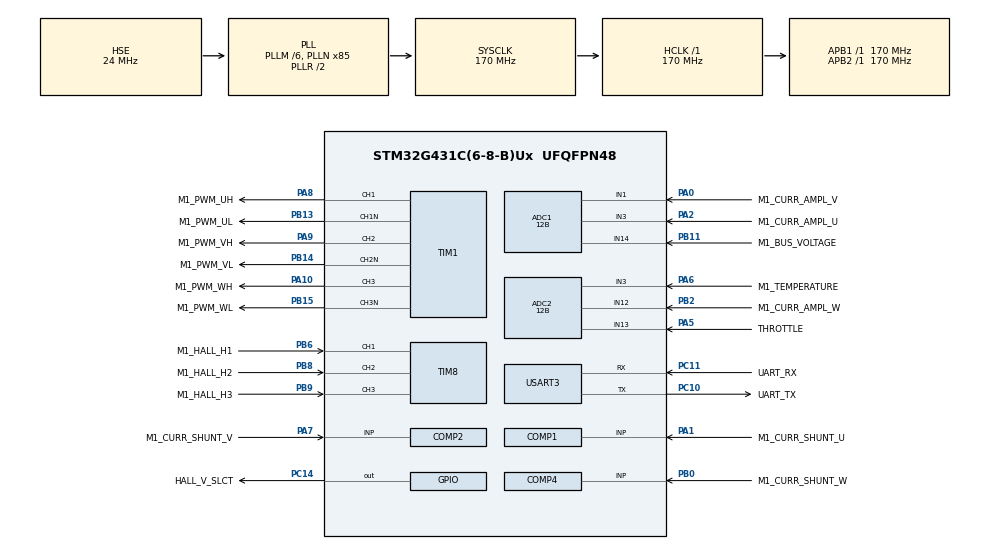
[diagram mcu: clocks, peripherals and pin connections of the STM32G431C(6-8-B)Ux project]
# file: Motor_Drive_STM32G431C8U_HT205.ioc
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ADC1.Channel-1\#ChannelRegularConversion=ADC_CHANNEL_14
ADC1.ClockPrescaler=ADC_CLOCK_ASYNC_DIV4
ADC1.ContinuousConvMode=DISABLE
ADC1.DMAContinuousRequests=DISABLE
ADC1.DataAlign=ADC_DATAALIGN_LEFT
ADC1.DiscontinuousConvMode=DISABLE
ADC1.EOCSelection=ADC_EOC_SINGLE_CONV
ADC1.EnableAnalogWatchDog1=false
ADC1.EnableAnalogWatchDog2=false
ADC1.EnableAnalogWatchDog3=false
ADC1.EnableInjectedConversion=ENABLE
ADC1.EnableRegularConversion=ENABLE
ADC1.ExternalTrigConv=ADC_SOFTWARE_START
ADC1.ExternalTrigConvEdge=ADC_EXTERNALTRIGCONVEDGE_NONE
ADC1.ExternalTrigInjecConv=ADC_EXTERNALTRIGINJEC_T1_TRGO
ADC1.ExternalTrigInjecConvEdge=ADC_EXTERNALTRIGINJECCONV_EDGE_RISING
ADC1.InjNumberOfConversion=2
ADC1.InjectedChannel-1\#ChannelInjectedConversion=ADC_CHANNEL_3
ADC1.InjectedChannel-2\#ChannelInjectedConversion=ADC_CHANNEL_1
ADC1.InjectedConvMode=None
ADC1.InjectedOffset-1\#ChannelInjectedConversion=0
ADC1.InjectedOffset-2\#ChannelInjectedConversion=0
ADC1.InjectedOffsetNumber-1\#ChannelInjectedConversion=ADC_OFFSET_NONE
ADC1.InjectedOffsetNumber-2\#ChannelInjectedConversion=ADC_OFFSET_NONE
ADC1.InjectedRank-1\#ChannelInjectedConversion=1
ADC1.InjectedRank-2\#ChannelInjectedConversion=2
ADC1.InjectedSamplingTime-1\#ChannelInjectedConversion=ADC_SAMPLETIME_6CYCLES_5
ADC1.InjectedSamplingTime-2\#ChannelInjectedConversion=ADC_SAMPLETIME_6CYCLES_5
ADC1.LowPowerAutoWait=DISABLE
ADC1.NbrOfConversion=1
ADC1.NbrOfConversionFlag=1
ADC1.Offset-1\#ChannelRegularConversion=0
ADC1.OffsetNumber-1\#ChannelRegularConversion=ADC_OFFSET_NONE
ADC1.Overrun=ADC_OVR_DATA_PRESERVED
ADC1.Rank-1\#ChannelRegularConversion=1
ADC1.Resolution=ADC_RESOLUTION_12B
ADC1.SamplingTime-1\#ChannelRegularConversion=ADC_SAMPLETIME_24CYCLES_5
ADC1.ScanConvMode=ADC_SCAN_ENABLE
ADC1.master=1
ADC2.Channel-1\#ChannelRegularConversion=ADC_CHANNEL_3
ADC2.Channel-3\#ChannelRegularConversion=ADC_CHANNEL_13
ADC2.ClockPrescaler=ADC_CLOCK_ASYNC_DIV4
ADC2.ContinuousConvMode=DISABLE
ADC2.DMAContinuousRequests=DISABLE
ADC2.DataAlign=ADC_DATAALIGN_LEFT
ADC2.DiscontinuousConvMode=DISABLE
ADC2.EOCSelection=ADC_EOC_SINGLE_CONV
ADC2.EnableAnalogWatchDog1=false
ADC2.EnableAnalogWatchDog2=false
ADC2.EnableAnalogWatchDog3=false
ADC2.EnableInjectedConversion=ENABLE
ADC2.EnableRegularConversion=ENABLE
ADC2.ExternalTrigConv=ADC_SOFTWARE_START
ADC2.ExternalTrigConvEdge=ADC_EXTERNALTRIGCONVEDGE_NONE
ADC2.ExternalTrigInjecConv=ADC_EXTERNALTRIGINJEC_T1_TRGO
ADC2.ExternalTrigInjecConvEdge=ADC_EXTERNALTRIGINJECCONV_EDGE_RISING
ADC2.InjNumberOfConversion=2
ADC2.InjectedChannel-1\#ChannelInjectedConversion=ADC_CHANNEL_1
ADC2.InjectedChannel-2\#ChannelInjectedConversion=ADC_CHANNEL_12
ADC2.InjectedConvMode=None
ADC2.InjectedOffset-1\#ChannelInjectedConversion=0
ADC2.InjectedOffset-2\#ChannelInjectedConversion=0
ADC2.InjectedOffsetNumber-1\#ChannelInjectedConversion=ADC_OFFSET_NONE
ADC2.InjectedOffsetNumber-2\#ChannelInjectedConversion=ADC_OFFSET_NONE
ADC2.InjectedRank-1\#ChannelInjectedConversion=1
ADC2.InjectedRank-2\#ChannelInjectedConversion=2
ADC2.InjectedSamplingTime-1\#ChannelInjectedConversion=ADC_SAMPLETIME_6CYCLES_5
ADC2.InjectedSamplingTime-2\#ChannelInjectedConversion=ADC_SAMPLETIME_6CYCLES_5
ADC2.LowPowerAutoWait=DISABLE
ADC2.NbrOfConversion=2
ADC2.NbrOfConversionFlag=1
ADC2.Offset-1\#ChannelRegularConversion=0
ADC2.OffsetNumber-1\#ChannelRegularConversion=ADC_OFFSET_NONE
ADC2.OffsetNumber-3\#ChannelRegularConversion=ADC_OFFSET_NONE
ADC2.Overrun=ADC_OVR_DATA_PRESERVED
ADC2.Rank-1\#ChannelRegularConversion=1
ADC2.Rank-3\#ChannelRegularConversion=2
ADC2.Resolution=ADC_RESOLUTION_12B
ADC2.SamplingTime-1\#ChannelRegularConversion=ADC_SAMPLETIME_24CYCLES_5
ADC2.SamplingTime-3\#ChannelRegularConversion=ADC_SAMPLETIME_24CYCLES_5
ADC2.ScanConvMode=ADC_SCAN_ENABLE
DAC3.DAC_Channel-DAC_OUT2_Int=DAC_CHANNEL_2
ExtraMW=MotorControl
ExtraMW.MotorControl.Config=MotorControl
ExtraMW.MotorControl.Mode=MotorControl
ExtraMW.MotorControl.Root=MCSDK_v5.4.6/MotorControl
ExtraMW.MotorControl.Template=templates
FREERTOS.Tasks01=mediumFrequency,24,128,startMediumFrequencyTask,As weak,NULL,Dynamic,NULL,NULL;safety,32,128,StartSafetyTask,As external,NULL,Dynamic,NULL,NULL;debugTask,8,128,startDebugTask,Default,NULL,Dynamic,NULL,NULL
Mcu.Family=STM32G4
Mcu.Name=STM32G431C(6-8-B)Ux
Mcu.Package=UFQFPN48
MotorControl.ADC_1_PERIPH=ADC1
MotorControl.ADC_2_PERIPH=ADC2
MotorControl.ADC_AHBPERIPH=RCC_AHBPeriph_ADC12
MotorControl.ADC_CLOCK_WB_DIV=4
MotorControl.ADC_CLOCK_WB_FREQ=42.5
MotorControl.ADC_PERIPH=ADC1
MotorControl.ADC_REFERENCE_VOLTAGE=3.30
MotorControl.ALIGNMENT_ANGLE_DEG=90
MotorControl.ALIGNMENT_DURATION=700
MotorControl.AMPLIFICATION_GAIN=20.00
MotorControl.ANGC={0,0,0,0,0,0,0,0}
MotorControl.BEMF_CONSISTENCY_GAIN=64
MotorControl.BEMF_CONSISTENCY_TOL=64
MotorControl.BKIN1_FILTER=0
MotorControl.BKIN2_FILTER=3
MotorControl.BKIN2_MODE=INT_MODE
MotorControl.BKIN_MODE=NONE
MotorControl.BOARD=CUSTOM
MotorControl.BRKIN2_GPIO_AF=GPIO_AF_12
MotorControl.BRKIN_GPIO_AF=GPIO_AF_2
MotorControl.BUS_VOLTAGE_READING=true
MotorControl.CCMRAM_ENABLED=false
MotorControl.CLOCK_FREQUENCY=CPU_CLK_170_MHZ
MotorControl.CLOCK_SOURCE=EXTERNAL
MotorControl.CONSTANT1_D=160849
MotorControl.CONSTANT1_Q=160849
MotorControl.CONSTANT2_QD=72703
MotorControl.CORD_BEMF_CONSISTENCY_GAIN=64
MotorControl.CORD_BEMF_CONSISTENCY_TOL=64
MotorControl.CORD_F1=16384
MotorControl.CORD_F2=16384
MotorControl.CORD_FIFO_DEPTH_01HZ=64
MotorControl.CORD_FIFO_DEPTH_DPP=64
MotorControl.CORD_GAIN1=-21504
MotorControl.CORD_GAIN2=24227
MotorControl.CORD_MAX_ACCEL_DPPP=887
MotorControl.CORD_MEAS_ERRORS_BEFORE_FAULTS=3
MotorControl.CORD_VARIANCE_THRESHOLD=4
MotorControl.CPU_CLK_170_MHZ=true
MotorControl.CTRBDID=29
MotorControl.CUBE_MX_VER=6.2.0
MotorControl.CURRENT_READING_TOPOLOGY=THREE_SHUNT_INDEPENDENT_RESOURCES
MotorControl.CURR_SAMPLING_TIME=6
MotorControl.DAC_EMULATED=false
MotorControl.DAC_FUNCTIONALITY=false
MotorControl.DAC_OCP_A_M1=DAC3_CH1
MotorControl.DAC_OCP_B_M1=DAC3_CH2
MotorControl.DAC_OCP_C_M1=DAC3_CH2
MotorControl.DAC_OVP_M1=DAC3_CH1
MotorControl.DAC_TIMER_CH1_GPIO_PIN=LL_GPIO_PIN_0
MotorControl.DAC_TIMER_CH1_GPIO_PORT=GPIOA
MotorControl.DAC_TIMER_CH2_GPIO_PIN=LL_GPIO_PIN_0
MotorControl.DAC_TIMER_CH2_GPIO_PORT=GPIOA
MotorControl.DAC_TIMER_SELECTION=TIM3
MotorControl.DC_CURRENT_RS_MEAS=10.00
MotorControl.DEBUG_DAC_CH1=false
MotorControl.DEBUG_DAC_CH2=false
MotorControl.DEFAULT_CONTROL_MODE=STC_TORQUE_MODE
MotorControl.DEFAULT_DAC_CHANNEL_1=MC_PROTOCOL_REG_I_A
MotorControl.DEFAULT_DAC_CHANNEL_2=MC_PROTOCOL_REG_I_B
MotorControl.DEFAULT_DAC_MOTOR=0
MotorControl.DEFAULT_FLUX_COMPONENT=0
MotorControl.DEFAULT_TARGET_SPEED_RPM=1500
MotorControl.DEFAULT_TORQUE_COMPONENT=0
MotorControl.DISSIPATIVE_BRAKE_POLARITY=DOUT_ACTIVE_HIGH
MotorControl.DRIVES_NUMBER_SELECTION=SINGLEDRIVE
MotorControl.EMERGENCY2_STOP_GPIO_PIN=LL_GPIO_PIN_11
MotorControl.EMERGENCY2_STOP_GPIO_PORT=GPIOA
MotorControl.EMERGENCY_STOP_GPIO_PIN=LL_GPIO_PIN_11
MotorControl.EMERGENCY_STOP_GPIO_PORT=GPIOA
MotorControl.ENABLE_SL_ALGO_FROM_PHASE=3
MotorControl.ENCODER_AVAILABLE=false
MotorControl.ENCODER_PPR=400
MotorControl.ENC_AVERAGING_FIFO_DEPTH=16
MotorControl.ENC_A_GPIO_PIN=LL_GPIO_PIN_0
MotorControl.ENC_A_GPIO_PORT=GPIOA
MotorControl.ENC_B_GPIO_PIN=LL_GPIO_PIN_3
MotorControl.ENC_B_GPIO_PORT=GPIOB
MotorControl.ENC_ICx_FILTER=119
MotorControl.ENC_INVERT_SPEED=false
MotorControl.ENC_MEAS_ERRORS_BEFORE_FAULTS=3
MotorControl.ENC_TIMER_REMAPPING=NO_REMAP_TIM2
MotorControl.ENC_TIMER_SELECTION=ENC_TIM2
MotorControl.ENC_USE_CH3=false
MotorControl.EXT_CLK_8_MHZ=true
MotorControl.EXT_CLOCK_FREQUENCY=EXT_CLK_8_MHZ
MotorControl.F1=16384
MotorControl.F2=16384
MotorControl.FEEDBACK_NET_FILTERING=false
MotorControl.FEED_FORWARD_CURRENT_REG_ENABLING=false
MotorControl.FINAL_I_ALIGNMENT=1548
MotorControl.FLUX_WEAKENING_ENABLING=false
MotorControl.FW_KIDIV=32768
MotorControl.FW_KI_GAIN=5000
MotorControl.FW_KPDIV=32768
MotorControl.FW_KP_GAIN=3000
MotorControl.FW_VOLTAGE_REF=985
MotorControl.GAIN1=-21504
MotorControl.GAIN2=24227
MotorControl.H1_GPIO_PIN=LL_GPIO_PIN_6
MotorControl.H1_GPIO_PORT=GPIOB
MotorControl.H2_GPIO_PIN=LL_GPIO_PIN_7
MotorControl.H2_GPIO_PORT=GPIOB
MotorControl.H3_GPIO_PIN=LL_GPIO_PIN_8
MotorControl.H3_GPIO_PORT=GPIOB
MotorControl.HALL_AVERAGING_FIFO_DEPTH=6
MotorControl.HALL_ICx_FILTER=190
MotorControl.HALL_MEAS_ERRORS_BEFORE_FAULTS=3
MotorControl.HALL_MTPA=false
MotorControl.HALL_PHASE_SHIFT=60
MotorControl.HALL_SENSORS=true
MotorControl.HALL_SENSORS_AVAILABLE=true
MotorControl.HALL_SENSORS_PLACEMENT=DEGREES_120
MotorControl.HALL_TIMER_REMAPPING=NO_REMAP_TIM4
MotorControl.HALL_TIMER_SELECTION=HALL_TIM4
MotorControl.HFI_AMPLITUDE=25
MotorControl.HFI_DC_0_COEFF=0.00146
MotorControl.HFI_DC_1_COEFF=0.002921
MotorControl.HFI_DC_2_COEFF=0.00146
MotorControl.HFI_DC_3_COEFF=1.889033
MotorControl.HFI_DC_4_COEFF=-0.894874
MotorControl.HFI_DEBUG_MODE=false
MotorControl.HFI_FREQUENCY=400
MotorControl.HFI_HIFRAMPLSCAN=25
MotorControl.HFI_HP_ID_0_COEFF=0.883002
MotorControl.HFI_HP_ID_1_COEFF=-1.766004
MotorControl.HFI_HP_ID_2_COEFF=0.883002
MotorControl.HFI_HP_ID_3_COEFF=1.752268
MotorControl.HFI_HP_ID_4_COEFF=-0.779739
MotorControl.HFI_IDH_DELAY=32400
MotorControl.HFI_LOCKFREQ=66
MotorControl.HFI_LP_ID_0_COEFF=0.021558
MotorControl.HFI_LP_ID_1_COEFF=0.043117
MotorControl.HFI_LP_ID_2_COEFF=0.021558
MotorControl.HFI_LP_ID_3_COEFF=1.543836
MotorControl.HFI_LP_ID_4_COEFF=-0.63007
MotorControl.HFI_MAXANGLEDIFF=3640
MotorControl.HFI_MINIMUM_SPEED_RPM=402
MotorControl.HFI_NOTCH_IQD_0_COEFF=0.941467
MotorControl.HFI_NOTCH_IQD_1_COEFF=-1.823778
MotorControl.HFI_NOTCH_IQD_2_COEFF=0.941467
MotorControl.HFI_NOTCH_IQD_3_COEFF=1.823778
MotorControl.HFI_NOTCH_IQD_4_COEFF=-0.882933
MotorControl.HFI_NSDETPOINTSSKIP=10
MotorControl.HFI_NSMAXDETPOINTS=20
MotorControl.HFI_NS_MIN_SAT_DIFF=0
MotorControl.HFI_PID_KIDIV=32768
MotorControl.HFI_PID_KI_DEFAULT=400
MotorControl.HFI_PID_KPDIV=16384
MotorControl.HFI_PID_KP_DEFAULT=800
MotorControl.HFI_PLL_KI_DEFAULT=0.00400
MotorControl.HFI_PLL_KP_DEFAULT=0.00060
MotorControl.HFI_RESTARTTIMESEC=0.1
MotorControl.HFI_RESTART_RPM_TH=(((HFI_STO_RPM_TH)+(STO_HFI_RPM_TH))/2)
MotorControl.HFI_REVERT_DIRECTION=true
MotorControl.HFI_SCANROTATIONSNO=3
MotorControl.HFI_SPD_BUFFER_DEPTH_01HZ=64
MotorControl.HFI_STEPANGLE=3640
MotorControl.HFI_STO_RPM_TH=OBS_MINIMUM_SPEED_RPM
MotorControl.HFI_WAITAFTERNS2=4
MotorControl.HFI_WAITBEFORESN=6
MotorControl.HFI_WAITSYNCH=20
MotorControl.HFI_WAITTRACK=20
MotorControl.HIGH_SIDE_BRAKE_STATE=false
MotorControl.HIGH_SIDE_IDLE_STATE=false
MotorControl.HW_COMPLEMENTED_LOW_SIDE=false
MotorControl.HW_DEAD_TIME_NS=100
MotorControl.HW_OV_CURRENT_PROT_BYPASS=false
MotorControl.ID_DEMAG=-7943
MotorControl.INRUSH_CURRLIMIT_AT_POWER_ON=true
MotorControl.INRUSH_CURRLIMIT_CHANGE_AFTER_MS=1000
MotorControl.INRUSH_CURRLIMIT_ENABLING=false
MotorControl.INRUSH_CURRLIMIT_GPIO_PIN=LL_GPIO_PIN_4
MotorControl.INRUSH_CURRLIMIT_GPIO_PORT=GPIOE
MotorControl.INRUSH_CURR_LIMITER_POLARITY=DOUT_ACTIVE_HIGH
MotorControl.INTERNAL_OVERCURRENTPROTECTION=true
MotorControl.INTERNAL_OVERVOLTAGEPROTECTION=false
MotorControl.IPs=CORDIC,NVIC,RCC,MotorControl,TIM1,COMP1,DAC3,COMP2,COMP4,ADC1,ADC2,TIM4,USART2,FREERTOS
MotorControl.IQMAX=7943
MotorControl.LCD_JOYSTICK_FUNCTIONALITY=false
MotorControl.LCD_MODE=LCD_FULL
MotorControl.LDLQ_RATIO=1.000
MotorControl.LOW_SIDE_BRAKE_STATE=false
MotorControl.LOW_SIDE_IDLE_STATE=false
MotorControl.LOW_SIDE_SIGNALS_ENABLING=LS_PWM_TIMER
MotorControl.LS=0.000200
MotorControl.MAX_APPLICATION_SPEED=400
MotorControl.MAX_MODULATION_93_PER_CENT=true
MotorControl.MAX_MODULATION_INDEX=MAX_MODULATION_93_PER_CENT
MotorControl.MCU=STM32G431CB
MotorControl.MCU_TYPE=STM32G431CB
MotorControl.MC_WORKBENCH_VERSION=5.4.6.21068
MotorControl.MEAS_ERRORS_BEFORE_FAULTS=3
MotorControl.MIN_APPLICATION_SPEED=0
MotorControl.MOTOR_MAX_SPEED_RPM=400
MotorControl.MOTOR_TYPE=PMSM
MotorControl.MOTOR_VOLTAGE_CONSTANT=88.0
MotorControl.MTPA_ENABLING=false
MotorControl.NB_CONSECUTIVE_TESTS=2
MotorControl.NOMINAL_BUS_VOLTAGE_V=42
MotorControl.NOMINAL_CURRENT=7943
MotorControl.OBS_MEAS_ERRORS_BEFORE_FAULTS=3
MotorControl.OBS_MINIMUM_SPEED_RPM=580
MotorControl.OCPA_DAC_INTERNAL_PIN=true
MotorControl.OCPA_INVERTINGINPUT=COMPX_InvertingInput_DAC3
MotorControl.OCPA_INVERTINGINPUT_DAC_OUT=OUT1
MotorControl.OCPA_INVERTINGINPUT_GPIO_PIN=LL_GPIO_PIN_4
MotorControl.OCPA_INVERTINGINPUT_GPIO_PORT=GPIOA
MotorControl.OCPA_INVERTINGINPUT_MODE=INT_MODE
MotorControl.OCPA_NONINVERTINGINPUT=COMP1_NonInvertingInput_PA1
MotorControl.OCPA_NONINVERTINGINPUT_GPIO_PIN=LL_GPIO_PIN_1
MotorControl.OCPA_NONINVERTINGINPUT_GPIO_PORT=GPIOA
MotorControl.OCPA_OUTPUT=COMP_Output_TIM1BKIN2
MotorControl.OCPA_OUTPUTPOL=COMP_OutputPol_NonInverted
MotorControl.OCPA_OUTPUT_GPIO_AF=GPIO_AF_2
MotorControl.OCPA_OUTPUT_GPIO_PIN=LL_GPIO_PIN_0
MotorControl.OCPA_OUTPUT_GPIO_PORT=GPIOA
MotorControl.OCPA_OUTPUT_MODE=INT_MODE
MotorControl.OCPA_SELECTION=COMP1
MotorControl.OCPB_DAC_INTERNAL_PIN=true
MotorControl.OCPB_INVERTINGINPUT=COMPX_InvertingInput_DAC3
MotorControl.OCPB_INVERTINGINPUT_DAC_OUT=OUT2
MotorControl.OCPB_INVERTINGINPUT_GPIO_PIN=LL_GPIO_PIN_4
MotorControl.OCPB_INVERTINGINPUT_GPIO_PORT=GPIOA
MotorControl.OCPB_INVERTINGINPUT_MODE=INT_MODE
MotorControl.OCPB_NONINVERTINGINPUT=COMP2_NonInvertingInput_PA7
MotorControl.OCPB_NONINVERTINGINPUT_GPIO_PIN=LL_GPIO_PIN_7
MotorControl.OCPB_NONINVERTINGINPUT_GPIO_PORT=GPIOA
MotorControl.OCPB_OUTPUT=COMP_Output_TIM1BKIN2
MotorControl.OCPB_OUTPUTPOL=COMP_OutputPol_NonInverted
MotorControl.OCPB_OUTPUT_GPIO_AF=GPIO_AF_2
MotorControl.OCPB_OUTPUT_GPIO_PIN=LL_GPIO_PIN_2
MotorControl.OCPB_OUTPUT_GPIO_PORT=GPIOA
MotorControl.OCPB_OUTPUT_MODE=INT_MODE
MotorControl.OCPB_SELECTION=COMP2
MotorControl.OCPC_DAC_INTERNAL_PIN=true
MotorControl.OCPC_INVERTINGINPUT=COMPX_InvertingInput_DAC3
MotorControl.OCPC_INVERTINGINPUT_DAC_OUT=OUT2
MotorControl.OCPC_INVERTINGINPUT_GPIO_PIN=LL_GPIO_PIN_4
MotorControl.OCPC_INVERTINGINPUT_GPIO_PORT=GPIOA
MotorControl.OCPC_INVERTINGINPUT_MODE=INT_MODE
MotorControl.OCPC_NONINVERTINGINPUT=COMP4_NonInvertingInput_PB0
MotorControl.OCPC_NONINVERTINGINPUT_GPIO_PIN=LL_GPIO_PIN_0
MotorControl.OCPC_NONINVERTINGINPUT_GPIO_PORT=GPIOB
MotorControl.OCPC_OUTPUT=COMP_Output_TIM1BKIN2
MotorControl.OCPC_OUTPUTPOL=COMP_OutputPol_NonInverted
MotorControl.OCPC_OUTPUT_GPIO_AF=GPIO_AF_2
MotorControl.OCPC_OUTPUT_GPIO_PIN=LL_GPIO_PIN_1
MotorControl.OCPC_OUTPUT_GPIO_PORT=GPIOB
MotorControl.OCPC_OUTPUT_MODE=INT_MODE
MotorControl.OCPC_SELECTION=COMP4
MotorControl.OCPREF=9532
MotorControl.OCP_COMP_THRESHOLD=0.50
MotorControl.OCP_FILTER=COMP_Mode_HighSpeed
MotorControl.OCP_INVERTINGINPUT=COMPX_InvertingInput_DAC3
MotorControl.OCP_INVERTINGINPUT_GPIO_PIN=LL_GPIO_PIN_4
MotorControl.OCP_INVERTINGINPUT_GPIO_PORT=GPIOA
MotorControl.OCP_INVERTINGINPUT_MODE=INT_MODE
MotorControl.OCP_NONINVERTINGINPUT=COMP2_NonInvertingInput_PA7
MotorControl.OCP_NONINVERTINGINPUT_GPIO_PIN=LL_GPIO_PIN_7
MotorControl.OCP_NONINVERTINGINPUT_GPIO_PORT=GPIOA
MotorControl.OCP_OUTPUT=COMP_Output_TIM1BKIN2
MotorControl.OCP_OUTPUTPOL=COMP_OutputPol_NonInverted
MotorControl.OCP_OUTPUT_GPIO_AF=GPIO_AF_2
MotorControl.OCP_OUTPUT_GPIO_PIN=LL_GPIO_PIN_2
MotorControl.OCP_OUTPUT_GPIO_PORT=GPIOA
MotorControl.OCP_OUTPUT_MODE=INT_MODE
MotorControl.OCP_SELECTION=COMP2
MotorControl.OFST={0,0,0,0,0,0,0,0}
MotorControl.ON_OVER_VOLTAGE=TURN_OFF_PWM
MotorControl.OPAMP1_INVERTINGINPUT=OPAMP1_InvertingInput_PGA
MotorControl.OPAMP1_INVERTINGINPUT_GPIO_PIN=LL_GPIO_PIN_3
MotorControl.OPAMP1_INVERTINGINPUT_GPIO_PORT=GPIOA
MotorControl.OPAMP1_INVERTINGINPUT_MODE=INT_MODE
MotorControl.OPAMP1_NONINVERTINGINPUT_PHA=OPAMP1_NonInvertingInput_PA1
MotorControl.OPAMP1_NONINVERTINGINPUT_PHA_GPIO_PIN=LL_GPIO_PIN_1
MotorControl.OPAMP1_NONINVERTINGINPUT_PHA_GPIO_PORT=GPIOA
MotorControl.OPAMP1_NONINVERTINGINPUT_PHB=OPAMP1_NonInvertingInput_PA7
MotorControl.OPAMP1_NONINVERTINGINPUT_PHB_GPIO_PIN=LL_GPIO_PIN_7
MotorControl.OPAMP1_NONINVERTINGINPUT_PHB_GPIO_PORT=GPIOA
MotorControl.OPAMP1_OUT_GPIO_PIN=LL_GPIO_PIN_2
MotorControl.OPAMP1_OUT_GPIO_PORT=GPIOA
MotorControl.OPAMP1_SELECTION=OPAMP1
MotorControl.OPAMP2_INVERTINGINPUT=OPAMP2_InvertingInput_PGA
MotorControl.OPAMP2_INVERTINGINPUT_GPIO_PIN=LL_GPIO_PIN_5
MotorControl.OPAMP2_INVERTINGINPUT_GPIO_PORT=GPIOA
MotorControl.OPAMP2_INVERTINGINPUT_MODE=INT_MODE
MotorControl.OPAMP2_NONINVERTINGINPUT_PHA=OPAMP2_NonInvertingInput_PB0
MotorControl.OPAMP2_NONINVERTINGINPUT_PHA_GPIO_PIN=LL_GPIO_PIN_0
MotorControl.OPAMP2_NONINVERTINGINPUT_PHA_GPIO_PORT=GPIOB
MotorControl.OPAMP2_NONINVERTINGINPUT_PHB=OPAMP2_NonInvertingInput_PA7
MotorControl.OPAMP2_NONINVERTINGINPUT_PHB_GPIO_PIN=LL_GPIO_PIN_7
MotorControl.OPAMP2_NONINVERTINGINPUT_PHB_GPIO_PORT=GPIOA
MotorControl.OPAMP2_NONINVERTINGINPUT_PHC=OPAMP2_NonInvertingInput_PB0
MotorControl.OPAMP2_NONINVERTINGINPUT_PHC_GPIO_PIN=LL_GPIO_PIN_0
MotorControl.OPAMP2_NONINVERTINGINPUT_PHC_GPIO_PORT=GPIOB
MotorControl.OPAMP2_OUT_GPIO_PIN=LL_GPIO_PIN_6
MotorControl.OPAMP2_OUT_GPIO_PORT=GPIOA
MotorControl.OPAMP2_SELECTION=OPAMP2
MotorControl.OPAMP3_INVERTINGINPUT=OPAMP1_InvertingInput_PGA
MotorControl.OPAMP3_INVERTINGINPUT_GPIO_PIN=LL_GPIO_PIN_0
MotorControl.OPAMP3_INVERTINGINPUT_GPIO_PORT=GPIOA
MotorControl.OPAMP3_INVERTINGINPUT_MODE=INT_MODE
MotorControl.OPAMP3_SELECTION=OPAMP1
MotorControl.OPAMP_INVERTINGINPUT=OPAMP1_InvertingInput_PGA
MotorControl.OPAMP_INVERTINGINPUT_GPIO_PIN=LL_GPIO_PIN_3
MotorControl.OPAMP_INVERTINGINPUT_GPIO_PORT=GPIOA
MotorControl.OPAMP_INVERTINGINPUT_MODE=INT_MODE
MotorControl.OPAMP_NONINVERTINGINPUT=OPAMP1_NonInvertingInput_PA7
MotorControl.OPAMP_NONINVERTINGINPUT_GPIO_PIN=LL_GPIO_PIN_7
MotorControl.OPAMP_NONINVERTINGINPUT_GPIO_PORT=GPIOA
MotorControl.OPAMP_OUT_GPIO_PIN=LL_GPIO_PIN_2
MotorControl.OPAMP_OUT_GPIO_PORT=GPIOA
MotorControl.OPAMP_PGACONNECT=OPAMP_PGAConnect_No
MotorControl.OPAMP_PGAGAIN=OPAMP_OPAMP_PGAGain_2
MotorControl.OPAMP_SELECTION=OPAMP1
MotorControl.OPAMP_TYPE_GAIN=INTERNAL
MotorControl.OPEN_LOOP_FOC=false
MotorControl.OPEN_LOOP_K=44
MotorControl.OPEN_LOOP_OFF=4400
MotorControl.OPEN_LOOP_SPEED_RAMP_DURATION_MS=1000
MotorControl.OPEN_LOOP_SPEED_RPM=100
MotorControl.OPEN_LOOP_VF=false
MotorControl.OPEN_LOOP_VOLTAGE_d=6000
MotorControl.OVERCURR_FEEDBACK_POLARITY=EMSTOP_ACTIVE_LOW
MotorControl.OVERCURR_PROTECTION_HW_DISABLING=DOUT_ACTIVE_HIGH
MotorControl.OVPREF=23830
MotorControl.OVP_FILTER=COMP_Mode_HighSpeed
MotorControl.OVP_INVERTINGINPUT=COMPX_InvertingInput_VREF
MotorControl.OVP_INVERTINGINPUT_GPIO_PIN=LL_GPIO_PIN_4
MotorControl.OVP_INVERTINGINPUT_GPIO_PORT=GPIOA
MotorControl.OVP_INVERTINGINPUT_MODE=INT_MODE
MotorControl.OVP_NONINVERTINGINPUT=COMP2_NonInvertingInput_PA7
MotorControl.OVP_NONINVERTINGINPUT_GPIO_PIN=LL_GPIO_PIN_7
MotorControl.OVP_NONINVERTINGINPUT_GPIO_PORT=GPIOA
MotorControl.OVP_OUTPUT=COMP_Output_TIM1BKIN
MotorControl.OVP_OUTPUTPOL=COMP_OutputPol_NonInverted
MotorControl.OVP_OUTPUT_GPIO_AF=GPIO_AF_2
MotorControl.OVP_OUTPUT_GPIO_PIN=LL_GPIO_PIN_2
MotorControl.OVP_OUTPUT_GPIO_PORT=GPIOA
MotorControl.OVP_OUTPUT_MODE=INT_MODE
MotorControl.OVP_SELECTION=COMP2
MotorControl.OV_CURR_BYPASS_GPIO_PIN=LL_GPIO_PIN_11
MotorControl.OV_CURR_BYPASS_GPIO_PORT=GPIOC
MotorControl.OV_TEMPERATURE_HYSTERESIS_C=10
MotorControl.OV_TEMPERATURE_PROT_ENABLING=true
MotorControl.OV_TEMPERATURE_THRESHOLD_C=70
MotorControl.OV_VOLTAGE_PROT_ENABLING=true
MotorControl.OV_VOLTAGE_THRESHOLD_V=49
MotorControl.PHASE1_DURATION=0
MotorControl.PHASE1_FINAL_CURRENT=0
MotorControl.PHASE1_FINAL_SPEED_RPM=0
MotorControl.PHASE2_DURATION=700
MotorControl.PHASE2_FINAL_CURRENT=476
MotorControl.PHASE2_FINAL_SPEED_RPM=0
MotorControl.PHASE3_DURATION=350
MotorControl.PHASE3_FINAL_CURRENT=556
MotorControl.PHASE3_FINAL_SPEED_RPM=630
MotorControl.PHASE4_DURATION=1150
MotorControl.PHASE4_FINAL_CURRENT=556
MotorControl.PHASE4_FINAL_SPEED_RPM=2700
MotorControl.PHASE5_DURATION=0
MotorControl.PHASE5_FINAL_CURRENT=556
MotorControl.PHASE5_FINAL_SPEED_RPM=2700
MotorControl.PHASE_CURRENTS_ADC=ADC1_2
MotorControl.PHASE_CURRENTS_CHANNEL=ADC_CHANNEL_9
MotorControl.PHASE_CURRENTS_GPIO_PIN=LL_GPIO_PIN_0
MotorControl.PHASE_CURRENTS_GPIO_PORT=GPIOA
MotorControl.PHASE_UH_GPIO_AF=GPIO_AF_6
MotorControl.PHASE_UH_GPIO_PIN=LL_GPIO_PIN_8
MotorControl.PHASE_UH_GPIO_PORT=GPIOA
MotorControl.PHASE_UH_POLARITY=H_ACTIVE_HIGH
MotorControl.PHASE_UL_GPIO_AF=GPIO_AF_6
MotorControl.PHASE_UL_GPIO_PIN=LL_GPIO_PIN_13
MotorControl.PHASE_UL_GPIO_PORT=GPIOB
MotorControl.PHASE_UL_POLARITY=L_ACTIVE_HIGH
MotorControl.PHASE_U_CURR_ADC=ADC1
MotorControl.PHASE_U_CURR_CHANNEL=ADC_CHANNEL_3
MotorControl.PHASE_U_GPIO_PIN=LL_GPIO_PIN_2
MotorControl.PHASE_U_GPIO_PORT=GPIOA
MotorControl.PHASE_VH_GPIO_AF=GPIO_AF_6
MotorControl.PHASE_VH_GPIO_PIN=LL_GPIO_PIN_9
MotorControl.PHASE_VH_GPIO_PORT=GPIOA
MotorControl.PHASE_VH_POLARITY=H_ACTIVE_HIGH
MotorControl.PHASE_VL_GPIO_AF=GPIO_AF_6
MotorControl.PHASE_VL_GPIO_PIN=LL_GPIO_PIN_14
MotorControl.PHASE_VL_GPIO_PORT=GPIOB
MotorControl.PHASE_VL_POLARITY=L_ACTIVE_HIGH
MotorControl.PHASE_V_CURR_ADC=ADC1_2
MotorControl.PHASE_V_CURR_CHANNEL=ADC_CHANNEL_1
MotorControl.PHASE_V_GPIO_PIN=LL_GPIO_PIN_0
MotorControl.PHASE_V_GPIO_PORT=GPIOA
MotorControl.PHASE_WH_GPIO_AF=GPIO_AF_6
MotorControl.PHASE_WH_GPIO_PIN=LL_GPIO_PIN_10
MotorControl.PHASE_WH_GPIO_PORT=GPIOA
MotorControl.PHASE_WH_POLARITY=H_ACTIVE_HIGH
MotorControl.PHASE_WL_GPIO_AF=GPIO_AF_4
MotorControl.PHASE_WL_GPIO_PIN=LL_GPIO_PIN_15
MotorControl.PHASE_WL_GPIO_PORT=GPIOB
MotorControl.PHASE_WL_POLARITY=L_ACTIVE_HIGH
MotorControl.PHASE_W_CURR_ADC=ADC2
MotorControl.PHASE_W_CURR_CHANNEL=ADC_CHANNEL_12
MotorControl.PHASE_W_GPIO_PIN=LL_GPIO_PIN_2
MotorControl.PHASE_W_GPIO_PORT=GPIOB
MotorControl.PID_FLUX_KD_DEFAULT=100
MotorControl.PID_FLUX_KI_DEFAULT=3218
MotorControl.PID_FLUX_KP_DEFAULT=3218
MotorControl.PID_SPEED_KD_DEFAULT=0
MotorControl.PID_SPEED_KI_DEFAULT=700
MotorControl.PID_SPEED_KP_DEFAULT=1000
MotorControl.PID_TORQUE_KD_DEFAULT=100
MotorControl.PID_TORQUE_KI_DEFAULT=3218
MotorControl.PID_TORQUE_KP_DEFAULT=3218
MotorControl.PLL_KI_GAIN=34
MotorControl.PLL_KP_GAIN=489
MotorControl.POLE_PAIR_NUM=23
MotorControl.POSITION_CTRL_ENABLING=false
MotorControl.PWBDID=0
MotorControl.PWM_FREQUENCY=20000
MotorControl.PWM_TIMER_REMAPPING=PWM_PARTIAL_REMAP
MotorControl.PWM_TIMER_SELECTION=PWM_TIM1
MotorControl.REGCONVADC=ADC1
MotorControl.REGULATION_EXECUTION_RATE=2
MotorControl.RS=0.50
MotorControl.RSHUNT=0.00200
MotorControl.RTOS=FREERTOS
MotorControl.RTOS_TIMER=TIM6
MotorControl.RTOS_USE_IRQ=false
MotorControl.R_BRAKE_GPIO_PIN=LL_GPIO_PIN_5
MotorControl.R_BRAKE_GPIO_PORT=GPIOE
MotorControl.R_BRAKE_SWITCH_OFF_THRES_V=39
MotorControl.SEGDIV=0
MotorControl.SERIAL_COMMUNICATION=true
MotorControl.SERIAL_COM_CHANNEL1=MC_PROTOCOL_REG_I_A
MotorControl.SERIAL_COM_CHANNEL2=MC_PROTOCOL_REG_I_A
MotorControl.SERIAL_COM_MODE=COM_BIDIRECTIONAL
MotorControl.SERIAL_COM_MOTOR=0
MotorControl.SHARED_SIGNAL_ENABLE=false
MotorControl.SINGLEDRIVE=true
MotorControl.SPD_DIFFERENTIAL_TERM_ENABLING=false
MotorControl.SPEED_BAND_LOWER_LIMIT=15
MotorControl.SPEED_BAND_UPPER_LIMIT=17
MotorControl.SPEED_LOOP_FREQUENCY_HZ=1000
MotorControl.SPEED_SENSOR_SELECTION=HALL_SENSORS
MotorControl.SP_KDDIV=16
MotorControl.SP_KIDIV=256
MotorControl.SP_KPDIV=16
MotorControl.STARTING_ANGLE_DEG=90
MotorControl.START_STOP_BTN=false
MotorControl.START_STOP_GPIO_PIN=LL_GPIO_PIN_13
MotorControl.START_STOP_GPIO_PORT=GPIOC
MotorControl.START_STOP_POLARITY=DIN_ACTIVE_LOW
MotorControl.START_STOP_POLARITY_EDGE=GPIO_NOPULL
MotorControl.STM32G431CB=true
MotorControl.STO_FIFO_DEPTH_01HZ=64
MotorControl.STO_FIFO_DEPTH_DPP=64
MotorControl.STO_HFI_RPM_TH=460
MotorControl.SW_DEADTIME_NS=500
MotorControl.SW_OV_CURRENT_PROT_ENABLING=true
MotorControl.T0_C=25
MotorControl.TEMPERATURE_READING=true
MotorControl.TEMP_ADC_SAMPLING_TIME=24
MotorControl.TEMP_FDBK_ADC=ADC2
MotorControl.TEMP_FDBK_CHANNEL=ADC_CHANNEL_3
MotorControl.TEMP_FDBK_GPIO_PIN=LL_GPIO_PIN_6
MotorControl.TEMP_FDBK_GPIO_PORT=GPIOA
MotorControl.TFDIFFERENTIAL_TERM_ENABLING=false
MotorControl.TF_KDDIV=8192
MotorControl.TF_KIDIV=16384
MotorControl.TF_KPDIV=4096
MotorControl.THREE_SHUNT_INDEPENDENT_RESOURCES=true
MotorControl.TNOISE_NS=2550
MotorControl.TRANSITION_DURATION=25
MotorControl.TRISE_NS=2550
MotorControl.T_MAX=70
MotorControl.UD_VOLTAGE_THRESHOLD_V=12
MotorControl.USART_REMAPPING=NO_REMAP_USART2
MotorControl.USART_RX_GPIO_PIN=LL_GPIO_PIN_4
MotorControl.USART_RX_GPIO_PORT=GPIOB
MotorControl.USART_SELECTION=USE_USART2
MotorControl.USART_SPEED=115200
MotorControl.USART_TX_GPIO_PIN=LL_GPIO_PIN_3
MotorControl.USART_TX_GPIO_PORT=GPIOB
MotorControl.USE_3OPAMPS=false
MotorControl.USE_INTERNAL_OPAMP=false
MotorControl.UV_VOLTAGE_PROT_ENABLING=false
MotorControl.V0_V=0.290
MotorControl.VARIANCE_THRESHOLD=0.1
MotorControl.VBUS_ADC=ADC1
MotorControl.VBUS_ADC_SAMPLING_TIME=24
MotorControl.VBUS_CHANNEL=ADC_CHANNEL_14
MotorControl.VBUS_GPIO_PIN=LL_GPIO_PIN_11
MotorControl.VBUS_GPIO_PORT=GPIOB
MotorControl.VBUS_PARTITIONING_FACTOR=0.0625
MotorControl.WB_to_Mx_template_version=21-02-18
MotorControl.WB_to_Mx_version=1.2.3
MotorControl.dV_dT=0.025
NVIC.ADC1_2_IRQn=true\:2\:0\:true\:true\:false\:3\:false\:true\:true
NVIC.PriorityGroup=NVIC_PRIORITYGROUP_4
NVIC.TIM1_BRK_TIM15_IRQn=true\:4\:0\:true\:true\:false\:1\:false\:true\:true
NVIC.TIM1_UP_TIM16_IRQn=true\:0\:0\:true\:true\:false\:2\:false\:true\:true
NVIC.TIM2_IRQn=true\:5\:0\:false\:false\:true\:true\:true\:true
NVIC.TIM3_IRQn=true\:5\:0\:false\:false\:true\:true\:true\:true
NVIC.TIM4_IRQn=true\:5\:0\:false\:false\:true\:true\:true\:true
NVIC.TIM6_DAC_IRQn=true\:0\:0\:false\:false\:true\:false\:false\:true
NVIC.TIM8_CC_IRQn=true\:5\:0\:false\:false\:true\:true\:true\:true
NVIC.TIM8_UP_IRQn=true\:5\:0\:false\:false\:true\:true\:true\:true
NVIC.TimeBase=TIM6_DAC_IRQn
NVIC.TimeBaseIP=TIM6
NVIC.USART3_IRQn=true\:5\:0\:false\:false\:true\:true\:true\:true
PA0.GPIO_Label=M1_CURR_AMPL_V
PA0.Signal=SharedAnalog_PA0
PA1.GPIO_Label=M1_CURR_SHUNT_U
PA1.Mode=INP
PA1.Signal=COMP1_INP
PA10.GPIO_Label=M1_PWM_WH
PA10.GPIO_PuPd=GPIO_PULLDOWN
PA10.GPIO_Speed=GPIO_SPEED_FREQ_HIGH
PA10.Signal=S_TIM1_CH3
PA13.GPIO_Label=TMS
PA13.Mode=Serial_Wire
PA13.Signal=SYS_JTMS-SWDIO
PA14.GPIO_Label=TCK
PA14.Mode=Serial_Wire
PA14.Signal=SYS_JTCK-SWCLK
PA2.GPIO_Label=M1_CURR_AMPL_U
PA2.Mode=IN3-Single-Ended
PA2.Signal=ADC1_IN3
PA5.GPIO_Label=THROTTLE
PA5.Mode=IN13-Single-Ended
PA5.Signal=ADC2_IN13
PA6.GPIO_Label=M1_TEMPERATURE
PA6.Mode=IN3-Single-Ended
PA6.Signal=ADC2_IN3
PA7.GPIO_Label=M1_CURR_SHUNT_V
PA7.Mode=INP
PA7.Signal=COMP2_INP
PA8.GPIO_Label=M1_PWM_UH
PA8.GPIO_PuPd=GPIO_PULLDOWN
PA8.GPIO_Speed=GPIO_SPEED_FREQ_HIGH
PA8.Signal=S_TIM1_CH1
PA9.GPIO_Label=M1_PWM_VH
PA9.GPIO_PuPd=GPIO_PULLDOWN
PA9.GPIO_Speed=GPIO_SPEED_FREQ_HIGH
PA9.Signal=S_TIM1_CH2
PB0.GPIO_Label=M1_CURR_SHUNT_W
PB0.Mode=INP
PB0.Signal=COMP4_INP
PB11.GPIO_Label=M1_BUS_VOLTAGE
PB11.Mode=IN14-Single-Ended
PB11.Signal=ADC1_IN14
PB13.GPIO_Label=M1_PWM_UL
PB13.GPIO_PuPd=GPIO_PULLDOWN
PB13.GPIO_Speed=GPIO_SPEED_FREQ_HIGH
PB13.Mode=PWM Generation1 CH1 CH1N
PB13.Signal=TIM1_CH1N
PB14.GPIO_Label=M1_PWM_VL
PB14.GPIO_PuPd=GPIO_PULLDOWN
PB14.GPIO_Speed=GPIO_SPEED_FREQ_HIGH
PB14.Mode=PWM Generation2 CH2 CH2N
PB14.Signal=TIM1_CH2N
PB15.GPIO_Label=M1_PWM_WL
PB15.GPIO_PuPd=GPIO_PULLDOWN
PB15.GPIO_Speed=GPIO_SPEED_FREQ_HIGH
PB15.Mode=PWM Generation3 CH3 CH3N
PB15.Signal=TIM1_CH3N
PB2.GPIO_Label=M1_CURR_AMPL_W
PB2.Mode=IN12-Single-Ended
PB2.Signal=ADC2_IN12
PB6.GPIO_Label=M1_HALL_H1
PB6.Signal=S_TIM8_CH1
PB8-BOOT0.GPIO_Label=M1_HALL_H2
PB8-BOOT0.Signal=S_TIM8_CH2
PB9.GPIO_Label=M1_HALL_H3
PB9.Signal=S_TIM8_CH3
PC10.GPIO_Label=UART_TX
PC10.Mode=Asynchronous
PC10.Signal=USART3_TX
PC11.GPIO_Label=UART_RX
PC11.Mode=Asynchronous
PC11.Signal=USART3_RX
PC14-OSC32_IN.GPIO_Label=HALL_V_SLCT
PC14-OSC32_IN.Signal=GPIO_Output
PF0-OSC_IN.Mode=HSE-External-Oscillator
PF0-OSC_IN.Signal=RCC_OSC_IN
PF1-OSC_OUT.Mode=HSE-External-Oscillator
PF1-OSC_OUT.Signal=RCC_OSC_OUT
ProjectManager.HeapSize=0x200
ProjectManager.StackSize=0x400
ProjectManager.TargetToolchain=MDK-ARM V5
RCC.ADC12CLockSelection=RCC_ADC12CLKSOURCE_PLL
RCC.ADC12Freq_Value=170000000
RCC.AHBFreq_Value=170000000
RCC.APB1Freq_Value=170000000
RCC.APB1TimFreq_Value=170000000
RCC.APB2Freq_Value=170000000
RCC.APB2TimFreq_Value=170000000
RCC.CortexFreq_Value=170000000
RCC.EXTERNAL_CLOCK_VALUE=12288000
RCC.HCLKFreq_Value=170000000
RCC.HSE_VALUE=24000000
RCC.HSI48_VALUE=48000000
RCC.HSI_VALUE=16000000
RCC.LSE_VALUE=32768
RCC.PLLM=RCC_PLLM_DIV6
RCC.PLLN=85
RCC.PLLSourceVirtual=RCC_PLLSOURCE_HSE
RCC.SYSCLKFreq_VALUE=170000000
RCC.SYSCLKSource=RCC_SYSCLKSOURCE_PLLCLK
RCC.USBFreq_Value=170000000
RCC.VCOOutputFreq_Value=340000000
SH.S_TIM1_CH1.0=TIM1_CH1,PWM Generation1 CH1 CH1N
SH.S_TIM1_CH2.0=TIM1_CH2,PWM Generation2 CH2 CH2N
SH.S_TIM1_CH3.0=TIM1_CH3,PWM Generation3 CH3 CH3N
SH.S_TIM8_CH1.0=TIM8_CH1,Xored_Inputs_Hall_Sensor_Interface
SH.S_TIM8_CH2.0=TIM8_CH2,Xored_Inputs_Hall_Sensor_Interface
SH.S_TIM8_CH3.0=TIM8_CH3,Xored_Inputs_Hall_Sensor_Interface
SH.SharedAnalog_PA0.0=ADC1_IN1,IN1-Single-Ended
SH.SharedAnalog_PA0.1=ADC2_IN1,IN1-Single-Ended
TIM1.AutoReloadPreload=TIM_AUTORELOAD_PRELOAD_DISABLE
TIM1.AutomaticOutput=TIM_AUTOMATICOUTPUT_DISABLE
TIM1.Break2Filter=3
TIM1.Break2Polarity=TIM_BREAK2POLARITY_HIGH
TIM1.Break2State=TIM_BREAK2_ENABLE
TIM1.BreakFilter=0
TIM1.BreakPolarity=TIM_BREAKPOLARITY_HIGH
TIM1.BreakState=TIM_BREAK_DISABLE
TIM1.Channel-PWM\ Generation1\ CH1\ CH1N=TIM_CHANNEL_1
TIM1.Channel-PWM\ Generation2\ CH2\ CH2N=TIM_CHANNEL_2
TIM1.Channel-PWM\ Generation3\ CH3\ CH3N=TIM_CHANNEL_3
TIM1.Channel-PWM\ Generation4\ No\ Output=TIM_CHANNEL_4
TIM1.ClearInputSource=TIM_CLEARINPUTSOURCE_NONE
TIM1.ClockDivision=TIM_CLOCKDIVISION_DIV2
TIM1.CounterMode=TIM_COUNTERMODE_CENTERALIGNED1
TIM1.DeadTime=((DEAD_TIME_COUNTS) / 2)
TIM1.LockLevel=TIM_LOCKLEVEL_1
TIM1.OCIdleState_1=TIM_OCIDLESTATE_RESET
TIM1.OCIdleState_2=TIM_OCIDLESTATE_RESET
TIM1.OCIdleState_3=TIM_OCIDLESTATE_RESET
TIM1.OCIdleState_4=TIM_OCIDLESTATE_RESET
TIM1.OCMode_PWM-PWM\ Generation1\ CH1\ CH1N=TIM_OCMODE_PWM1
TIM1.OCMode_PWM-PWM\ Generation2\ CH2\ CH2N=TIM_OCMODE_PWM1
TIM1.OCMode_PWM-PWM\ Generation3\ CH3\ CH3N=TIM_OCMODE_PWM1
TIM1.OCMode_PWM-PWM\ Generation4\ No\ Output=TIM_OCMODE_PWM2
TIM1.OCNIdleState_1=TIM_OCNIDLESTATE_RESET
TIM1.OCNIdleState_2=TIM_OCNIDLESTATE_RESET
TIM1.OCNIdleState_3=TIM_OCNIDLESTATE_RESET
TIM1.OCNPolarity_1=TIM_OCNPOLARITY_HIGH
TIM1.OCNPolarity_2=TIM_OCNPOLARITY_HIGH
TIM1.OCNPolarity_3=TIM_OCNPOLARITY_HIGH
TIM1.OCPolarity_1=TIM_OCPOLARITY_HIGH
TIM1.OCPolarity_2=TIM_OCPOLARITY_HIGH
TIM1.OCPolarity_3=TIM_OCPOLARITY_HIGH
TIM1.OCPolarity_4=TIM_OCPOLARITY_HIGH
TIM1.OffStateIDLEMode=TIM_OSSI_ENABLE
TIM1.OffStateRunMode=TIM_OSSR_ENABLE
TIM1.PeriodNoDither=((PWM_PERIOD_CYCLES) / 2)
TIM1.Prescaler=((TIM_CLOCK_DIVIDER) - 1)
TIM1.RepetitionCounter=(REP_COUNTER)
TIM1.SourceBRK2COMP1=TIM_BREAKINPUTSOURCE_ENABLE
TIM1.SourceBRK2COMP1Polarity=TIM_BREAKINPUTSOURCE_POLARITY_HIGH
TIM1.SourceBRK2COMP2=TIM_BREAKINPUTSOURCE_ENABLE
TIM1.SourceBRK2COMP2Polarity=TIM_BREAKINPUTSOURCE_POLARITY_HIGH
TIM1.SourceBRK2COMP4=TIM_BREAKINPUTSOURCE_ENABLE
TIM1.SourceBRK2COMP4Polarity=TIM_BREAKINPUTSOURCE_POLARITY_HIGH
TIM1.SourceBRK2DigInput=TIM_BREAKINPUTSOURCE_DISABLE
TIM1.TIM_MasterOutputTrigger=TIM_TRGO_OC4REF
TIM1.TIM_MasterOutputTrigger2=TIM_TRGO2_RESET
TIM1.TIM_MasterSlaveMode=TIM_MASTERSLAVEMODE_DISABLE
TIM1.TIM_SlaveMode=TIM_SLAVEMODE_TRIGGER
TIM2.Channel-Output\ Compare1\ No\ Output=TIM_CHANNEL_1
TIM2.ClearInputSource=TIM_CLEARINPUTSOURCE_NONE
TIM2.OCMode_1=TIM_OCMODE_ACTIVE
TIM3.Channel-Output\ Compare1\ No\ Output=TIM_CHANNEL_1
TIM3.OCMode_1=TIM_OCMODE_ACTIVE
TIM3.TIM3_ETR_REMAP-TriggerSource_ETR_Remap_TIM3=TIM_TIM3_ETR_COMP2
TIM4.Channel-Output\ Compare1\ No\ Output=TIM_CHANNEL_1
TIM4.OCMode_1=TIM_OCMODE_ACTIVE
TIM4.TIM4_ETR_REMAP-TriggerSource_ETR_Remap_TIM4=TIM_TIM4_ETR_COMP4
TIM8.IC1Filter=M1_HALL_IC_FILTER
TIM8.TIM_MasterOutputTrigger2=TIM_TRGO2_OC2REF
USART3.VirtualMode-Asynchronous=VM_ASYNC
VP_COMP1_VS_DAC3OUT1.Mode=INM_DAC3OUT1
VP_COMP2_VS_DAC3OUT2.Mode=INM_DAC3OUT2
VP_COMP4_VS_DAC3OUT2.Mode=INM_DAC3OUT2
VP_CORDIC_VS_CORDIC.Mode=CORDIC_Activate
VP_DAC3_VS_DACI1.Mode=DAC_OUT1_Int
VP_DAC3_VS_DACI2.Mode=DAC_OUT2_Int
VP_FREERTOS_VS_CMSIS_V2.Mode=CMSIS_V2
VP_MotorControl_MC_ENABLED.Mode=Enabled
VP_SYS_VS_DBSignals.Mode=DisableDeadBatterySignals
VP_SYS_VS_tim6.Mode=TIM6
VP_TIM1_VS_ClockSourceITR.Mode=TriggerSource_ITR1
VP_TIM1_VS_ControllerModeTrigger.Mode=Trigger Mode
VP_TIM1_VS_no_output4.Mode=PWM Generation4 No Output
VP_TIM2_VS_ControllerModeTrigger.Mode=Trigger Mode
VP_TIM2_VS_NoETR.Mode=TriggerSource_ETR_Remap_TIM2
VP_TIM2_VS_no_output1.Mode=Output Compare1 No Output
VP_TIM3_VS_ControllerModeTrigger.Mode=Trigger Mode
VP_TIM3_VS_NoETR.Mode=TriggerSource_ETR_Remap_TIM3
VP_TIM3_VS_no_output1.Mode=Output Compare1 No Output
VP_TIM4_VS_ControllerModeTrigger.Mode=Trigger Mode
VP_TIM4_VS_NoETR.Mode=TriggerSource_ETR_Remap_TIM4
VP_TIM4_VS_no_output1.Mode=Output Compare1 No Output
board=custom

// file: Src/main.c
/* USER CODE BEGIN Header */
/**
  ******************************************************************************
  * @file           : main.c
  * @brief          : Main program body
  ******************************************************************************
  * @attention
  *
  * <h2><center>&copy; Copyright (c) 2021 STMicroelectronics.
  * All rights reserved.</center></h2>
  *
  * This software component is licensed by ST under Ultimate Liberty license
  * SLA0044, the "License"; You may not use this file except in compliance with
  * the License. You may obtain a copy of the License at:
  *                             www.st.com/SLA0044
  *
  ******************************************************************************
  */
/* USER CODE END Header */
#include "main.h"
#include "cmsis_os.h"

/* USER CODE BEGIN Includes */

#include "throttle.h"
#include "mc_tasks.h"
#include "mc_config.h"
#include "flashconfig.h"
#include "timers.h"

/* USER CODE END Includes */

/* USER CODE BEGIN PD */

#define LOGGING_SIZE 100

/* USER CODE END PD */

ADC_HandleTypeDef hadc1;
ADC_HandleTypeDef hadc2;

COMP_HandleTypeDef hcomp1;
COMP_HandleTypeDef hcomp2;
COMP_HandleTypeDef hcomp4;

CORDIC_HandleTypeDef hcordic;

DAC_HandleTypeDef hdac3;

TIM_HandleTypeDef htim1;
TIM_HandleTypeDef htim2;
TIM_HandleTypeDef htim3;
TIM_HandleTypeDef htim4;
TIM_HandleTypeDef htim8;

UART_HandleTypeDef huart3;

/* Definitions for mediumFrequency */
osThreadId_t mediumFrequencyHandle;
const osThreadAttr_t mediumFrequency_attributes = {
  .name = "mediumFrequency",
  .priority = (osPriority_t) osPriorityNormal,
  .stack_size = 128 * 4
};
/* Definitions for safety */
osThreadId_t safetyHandle;
const osThreadAttr_t safety_attributes = {
  .name = "safety",
  .priority = (osPriority_t) osPriorityAboveNormal,
  .stack_size = 128 * 4
};
/* Definitions for throttleTask */
osThreadId_t throttleTaskHandle;
const osThreadAttr_t throttleTask_attributes = {
  .name = "throttleTask",
  .priority = (osPriority_t) osPriorityLow,
  .stack_size = 128 * 4
};
/* USER CODE BEGIN PV */

/* Definitions for loggingTask */
osThreadId_t loggingTaskHandle;
const osThreadAttr_t loggingTask_attributes = {
  .name = "loggingTask",
  .priority = (osPriority_t) osPriorityLow,
  .stack_size = 128 * 4
};

uint8_t UART3_rxBuffer[1] = {0};

int16_t loggingTemperature[LOGGING_SIZE];
int32_t loggingSpeed[LOGGING_SIZE];

/* USER CODE END PV */

void SystemClock_Config(void);
static void MX_GPIO_Init(void);
static void MX_ADC1_Init(void);
static void MX_ADC2_Init(void);
static void MX_COMP1_Init(void);
static void MX_COMP2_Init(void);
static void MX_COMP4_Init(void);
static void MX_CORDIC_Init(void);
static void MX_DAC3_Init(void);
static void MX_TIM1_Init(void);
static void MX_TIM4_Init(void);
static void MX_TIM8_Init(void);
static void MX_USART3_UART_Init(void);
static void MX_TIM2_Init(void);
static void MX_TIM3_Init(void);
void startMediumFrequencyTask(void *argument);
extern void StartSafetyTask(void *argument);
void startThrottleTask(void *argument);

static void MX_NVIC_Init(void);
/* USER CODE BEGIN PFP */

void startLoggingTask(void *argument);

/* USER CODE END PFP */

int main(void)
{

  /* MCU Configuration--------------------------------------------------------*/

  /* Reset of all peripherals, Initializes the Flash interface and the Systick. */
  HAL_Init();

  /* Configure the system clock */
  SystemClock_Config();

  /* USER CODE BEGIN SysInit */

	HAL_Delay(250);

  /* USER CODE END SysInit */

  /* Initialize all configured peripherals */
	MX_TIM8_Init();
  MX_GPIO_Init();
  MX_ADC1_Init();
  MX_ADC2_Init();
  MX_COMP1_Init();
  MX_COMP2_Init();
  MX_COMP4_Init();
  MX_CORDIC_Init();
  MX_DAC3_Init();
  MX_TIM1_Init();
  MX_TIM4_Init();
  MX_MotorControl_Init();
  MX_USART3_UART_Init();
  MX_TIM2_Init();
  MX_TIM3_Init();

  /* Initialize interrupts */
  MX_NVIC_Init();
  /* USER CODE BEGIN 2 */

	HAL_UART_Receive_IT (&huart3, UART3_rxBuffer, 1);

  /* USER CODE END 2 */

  /* Init scheduler */
  osKernelInitialize();

  /* Create the thread(s) */
  /* creation of mediumFrequency */
  mediumFrequencyHandle = osThreadNew(startMediumFrequencyTask, NULL, &mediumFrequency_attributes);

  /* creation of safety */
  safetyHandle = osThreadNew(StartSafetyTask, NULL, &safety_attributes);

  /* creation of throttleTask */
  throttleTaskHandle = osThreadNew(startThrottleTask, NULL, &throttleTask_attributes);

  /* USER CODE BEGIN RTOS_THREADS */

	loggingTaskHandle = osThreadNew(startLoggingTask, NULL, &loggingTask_attributes);

  /* USER CODE END RTOS_THREADS */

  /* Start scheduler */
  osKernelStart();

  /* We should never get here as control is now taken by the scheduler */
  /* Infinite loop */
  while (1)
  {

  }
}

void SystemClock_Config(void)
{
  RCC_OscInitTypeDef RCC_OscInitStruct = {0};
  RCC_ClkInitTypeDef RCC_ClkInitStruct = {0};
  RCC_PeriphCLKInitTypeDef PeriphClkInit = {0};

  /** Configure the main internal regulator output voltage
  */
  HAL_PWREx_ControlVoltageScaling(PWR_REGULATOR_VOLTAGE_SCALE1_BOOST);
  /** Initializes the RCC Oscillators according to the specified parameters
  * in the RCC_OscInitTypeDef structure.
  */
  RCC_OscInitStruct.OscillatorType = RCC_OSCILLATORTYPE_HSE;
  RCC_OscInitStruct.HSEState = RCC_HSE_ON;
  RCC_OscInitStruct.PLL.PLLState = RCC_PLL_ON;
  RCC_OscInitStruct.PLL.PLLSource = RCC_PLLSOURCE_HSE;
  RCC_OscInitStruct.PLL.PLLM = RCC_PLLM_DIV6;
  RCC_OscInitStruct.PLL.PLLN = 85;
  RCC_OscInitStruct.PLL.PLLP = RCC_PLLP_DIV2;
  RCC_OscInitStruct.PLL.PLLQ = RCC_PLLQ_DIV2;
  RCC_OscInitStruct.PLL.PLLR = RCC_PLLR_DIV2;
  if (HAL_RCC_OscConfig(&RCC_OscInitStruct) != HAL_OK)
  {
    Error_Handler();
  }
  /** Initializes the CPU, AHB and APB buses clocks
  */
  RCC_ClkInitStruct.ClockType = RCC_CLOCKTYPE_HCLK|RCC_CLOCKTYPE_SYSCLK
                              |RCC_CLOCKTYPE_PCLK1|RCC_CLOCKTYPE_PCLK2;
  RCC_ClkInitStruct.SYSCLKSource = RCC_SYSCLKSOURCE_PLLCLK;
  RCC_ClkInitStruct.AHBCLKDivider = RCC_SYSCLK_DIV1;
  RCC_ClkInitStruct.APB1CLKDivider = RCC_HCLK_DIV1;
  RCC_ClkInitStruct.APB2CLKDivider = RCC_HCLK_DIV1;

  if (HAL_RCC_ClockConfig(&RCC_ClkInitStruct, FLASH_LATENCY_4) != HAL_OK)
  {
    Error_Handler();
  }
  /** Initializes the peripherals clocks
  */
  PeriphClkInit.PeriphClockSelection = RCC_PERIPHCLK_USART3|RCC_PERIPHCLK_ADC12;
  PeriphClkInit.Usart3ClockSelection = RCC_USART3CLKSOURCE_PCLK1;
  PeriphClkInit.Adc12ClockSelection = RCC_ADC12CLKSOURCE_PLL;
  if (HAL_RCCEx_PeriphCLKConfig(&PeriphClkInit) != HAL_OK)
  {
    Error_Handler();
  }
}

/**
  * @brief NVIC Configuration.
  * @retval None
  */
static void MX_NVIC_Init(void)
{
  /* TIM1_BRK_TIM15_IRQn interrupt configuration */
  HAL_NVIC_SetPriority(TIM1_BRK_TIM15_IRQn, 4, 0);
  HAL_NVIC_EnableIRQ(TIM1_BRK_TIM15_IRQn);
  /* TIM1_UP_TIM16_IRQn interrupt configuration */
  HAL_NVIC_SetPriority(TIM1_UP_TIM16_IRQn, 0, 0);
  HAL_NVIC_EnableIRQ(TIM1_UP_TIM16_IRQn);
  /* ADC1_2_IRQn interrupt configuration */
  HAL_NVIC_SetPriority(ADC1_2_IRQn, 2, 0);
  HAL_NVIC_EnableIRQ(ADC1_2_IRQn);
}

static void MX_ADC1_Init(void)
{

  ADC_MultiModeTypeDef multimode = {0};
  ADC_InjectionConfTypeDef sConfigInjected = {0};
  ADC_ChannelConfTypeDef sConfig = {0};

  /** Common config
  */
  hadc1.Instance = ADC1;
  hadc1.Init.ClockPrescaler = ADC_CLOCK_ASYNC_DIV4;
  hadc1.Init.Resolution = ADC_RESOLUTION_12B;
  hadc1.Init.DataAlign = ADC_DATAALIGN_LEFT;
  hadc1.Init.GainCompensation = 0;
  hadc1.Init.ScanConvMode = ADC_SCAN_ENABLE;
  hadc1.Init.EOCSelection = ADC_EOC_SINGLE_CONV;
  hadc1.Init.LowPowerAutoWait = DISABLE;
  hadc1.Init.ContinuousConvMode = DISABLE;
  hadc1.Init.NbrOfConversion = 1;
  hadc1.Init.DiscontinuousConvMode = DISABLE;
  hadc1.Init.ExternalTrigConv = ADC_SOFTWARE_START;
  hadc1.Init.ExternalTrigConvEdge = ADC_EXTERNALTRIGCONVEDGE_NONE;
  hadc1.Init.DMAContinuousRequests = DISABLE;
  hadc1.Init.Overrun = ADC_OVR_DATA_PRESERVED;
  hadc1.Init.OversamplingMode = DISABLE;
  if (HAL_ADC_Init(&hadc1) != HAL_OK)
  {
    Error_Handler();
  }
  /** Configure the ADC multi-mode
  */
  multimode.Mode = ADC_MODE_INDEPENDENT;
  if (HAL_ADCEx_MultiModeConfigChannel(&hadc1, &multimode) != HAL_OK)
  {
    Error_Handler();
  }
  /** Configure Injected Channel
  */
  sConfigInjected.InjectedChannel = ADC_CHANNEL_3;
  sConfigInjected.InjectedRank = ADC_INJECTED_RANK_1;
  sConfigInjected.InjectedSamplingTime = ADC_SAMPLETIME_6CYCLES_5;
  sConfigInjected.InjectedSingleDiff = ADC_SINGLE_ENDED;
  sConfigInjected.InjectedOffsetNumber = ADC_OFFSET_NONE;
  sConfigInjected.InjectedOffset = 0;
  sConfigInjected.InjectedNbrOfConversion = 2;
  sConfigInjected.InjectedDiscontinuousConvMode = DISABLE;
  sConfigInjected.AutoInjectedConv = DISABLE;
  sConfigInjected.QueueInjectedContext = DISABLE;
  sConfigInjected.ExternalTrigInjecConv = ADC_EXTERNALTRIGINJEC_T1_TRGO;
  sConfigInjected.ExternalTrigInjecConvEdge = ADC_EXTERNALTRIGINJECCONV_EDGE_RISING;
  sConfigInjected.InjecOversamplingMode = DISABLE;
  if (HAL_ADCEx_InjectedConfigChannel(&hadc1, &sConfigInjected) != HAL_OK)
  {
    Error_Handler();
  }
  /** Configure Injected Channel
  */
  sConfigInjected.InjectedChannel = ADC_CHANNEL_1;
  sConfigInjected.InjectedRank = ADC_INJECTED_RANK_2;
  if (HAL_ADCEx_InjectedConfigChannel(&hadc1, &sConfigInjected) != HAL_OK)
  {
    Error_Handler();
  }
  /** Configure Regular Channel
  */
  sConfig.Channel = ADC_CHANNEL_14;
  sConfig.Rank = ADC_REGULAR_RANK_1;
  sConfig.SamplingTime = ADC_SAMPLETIME_24CYCLES_5;
  sConfig.SingleDiff = ADC_SINGLE_ENDED;
  sConfig.OffsetNumber = ADC_OFFSET_NONE;
  sConfig.Offset = 0;
  if (HAL_ADC_ConfigChannel(&hadc1, &sConfig) != HAL_OK)
  {
    Error_Handler();
  }

}

static void MX_ADC2_Init(void)
{

  ADC_InjectionConfTypeDef sConfigInjected = {0};
  ADC_ChannelConfTypeDef sConfig = {0};

  /** Common config
  */
  hadc2.Instance = ADC2;
  hadc2.Init.ClockPrescaler = ADC_CLOCK_ASYNC_DIV4;
  hadc2.Init.Resolution = ADC_RESOLUTION_12B;
  hadc2.Init.DataAlign = ADC_DATAALIGN_LEFT;
  hadc2.Init.GainCompensation = 0;
  hadc2.Init.ScanConvMode = ADC_SCAN_ENABLE;
  hadc2.Init.EOCSelection = ADC_EOC_SINGLE_CONV;
  hadc2.Init.LowPowerAutoWait = DISABLE;
  hadc2.Init.ContinuousConvMode = DISABLE;
  hadc2.Init.NbrOfConversion = 2;
  hadc2.Init.DiscontinuousConvMode = DISABLE;
  hadc2.Init.ExternalTrigConv = ADC_SOFTWARE_START;
  hadc2.Init.ExternalTrigConvEdge = ADC_EXTERNALTRIGCONVEDGE_NONE;
  hadc2.Init.DMAContinuousRequests = DISABLE;
  hadc2.Init.Overrun = ADC_OVR_DATA_PRESERVED;
  hadc2.Init.OversamplingMode = DISABLE;
  if (HAL_ADC_Init(&hadc2) != HAL_OK)
  {
    Error_Handler();
  }
  /** Configure Injected Channel
  */
  sConfigInjected.InjectedChannel = ADC_CHANNEL_1;
  sConfigInjected.InjectedRank = ADC_INJECTED_RANK_1;
  sConfigInjected.InjectedSamplingTime = ADC_SAMPLETIME_6CYCLES_5;
  sConfigInjected.InjectedSingleDiff = ADC_SINGLE_ENDED;
  sConfigInjected.InjectedOffsetNumber = ADC_OFFSET_NONE;
  sConfigInjected.InjectedOffset = 0;
  sConfigInjected.InjectedNbrOfConversion = 2;
  sConfigInjected.InjectedDiscontinuousConvMode = DISABLE;
  sConfigInjected.AutoInjectedConv = DISABLE;
  sConfigInjected.QueueInjectedContext = DISABLE;
  sConfigInjected.ExternalTrigInjecConv = ADC_EXTERNALTRIGINJEC_T1_TRGO;
  sConfigInjected.ExternalTrigInjecConvEdge = ADC_EXTERNALTRIGINJECCONV_EDGE_RISING;
  sConfigInjected.InjecOversamplingMode = DISABLE;
  if (HAL_ADCEx_InjectedConfigChannel(&hadc2, &sConfigInjected) != HAL_OK)
  {
    Error_Handler();
  }
  /** Configure Injected Channel
  */
  sConfigInjected.InjectedChannel = ADC_CHANNEL_12;
  sConfigInjected.InjectedRank = ADC_INJECTED_RANK_2;
  if (HAL_ADCEx_InjectedConfigChannel(&hadc2, &sConfigInjected) != HAL_OK)
  {
    Error_Handler();
  }
  /** Configure Regular Channel
  */
  sConfig.Channel = ADC_CHANNEL_3;
  sConfig.Rank = ADC_REGULAR_RANK_1;
  sConfig.SamplingTime = ADC_SAMPLETIME_24CYCLES_5;
  sConfig.SingleDiff = ADC_SINGLE_ENDED;
  sConfig.OffsetNumber = ADC_OFFSET_NONE;
  sConfig.Offset = 0;
  if (HAL_ADC_ConfigChannel(&hadc2, &sConfig) != HAL_OK)
  {
    Error_Handler();
  }
  /** Configure Regular Channel
  */
  sConfig.Channel = ADC_CHANNEL_13;
  sConfig.Rank = ADC_REGULAR_RANK_2;
  if (HAL_ADC_ConfigChannel(&hadc2, &sConfig) != HAL_OK)
  {
    Error_Handler();
  }

}

static void MX_COMP1_Init(void)
{

  hcomp1.Instance = COMP1;
  hcomp1.Init.InputPlus = COMP_INPUT_PLUS_IO1;
  hcomp1.Init.InputMinus = COMP_INPUT_MINUS_DAC3_CH1;
  hcomp1.Init.OutputPol = COMP_OUTPUTPOL_NONINVERTED;
  hcomp1.Init.Hysteresis = COMP_HYSTERESIS_NONE;
  hcomp1.Init.BlankingSrce = COMP_BLANKINGSRC_NONE;
  hcomp1.Init.TriggerMode = COMP_TRIGGERMODE_NONE;
  if (HAL_COMP_Init(&hcomp1) != HAL_OK)
  {
    Error_Handler();
  }

}

static void MX_COMP2_Init(void)
{

  hcomp2.Instance = COMP2;
  hcomp2.Init.InputPlus = COMP_INPUT_PLUS_IO1;
  hcomp2.Init.InputMinus = COMP_INPUT_MINUS_DAC3_CH2;
  hcomp2.Init.OutputPol = COMP_OUTPUTPOL_NONINVERTED;
  hcomp2.Init.Hysteresis = COMP_HYSTERESIS_NONE;
  hcomp2.Init.BlankingSrce = COMP_BLANKINGSRC_NONE;
  hcomp2.Init.TriggerMode = COMP_TRIGGERMODE_NONE;
  if (HAL_COMP_Init(&hcomp2) != HAL_OK)
  {
    Error_Handler();
  }

}

static void MX_COMP4_Init(void)
{

  hcomp4.Instance = COMP4;
  hcomp4.Init.InputPlus = COMP_INPUT_PLUS_IO1;
  hcomp4.Init.InputMinus = COMP_INPUT_MINUS_DAC3_CH2;
  hcomp4.Init.OutputPol = COMP_OUTPUTPOL_NONINVERTED;
  hcomp4.Init.Hysteresis = COMP_HYSTERESIS_NONE;
  hcomp4.Init.BlankingSrce = COMP_BLANKINGSRC_NONE;
  hcomp4.Init.TriggerMode = COMP_TRIGGERMODE_NONE;
  if (HAL_COMP_Init(&hcomp4) != HAL_OK)
  {
    Error_Handler();
  }

}

static void MX_CORDIC_Init(void)
{

  hcordic.Instance = CORDIC;
  if (HAL_CORDIC_Init(&hcordic) != HAL_OK)
  {
    Error_Handler();
  }

}

static void MX_DAC3_Init(void)
{

  DAC_ChannelConfTypeDef sConfig = {0};

  /** DAC Initialization
  */
  hdac3.Instance = DAC3;
  if (HAL_DAC_Init(&hdac3) != HAL_OK)
  {
    Error_Handler();
  }
  /** DAC channel OUT1 config
  */
  sConfig.DAC_HighFrequency = DAC_HIGH_FREQUENCY_INTERFACE_MODE_AUTOMATIC;
  sConfig.DAC_DMADoubleDataMode = DISABLE;
  sConfig.DAC_SignedFormat = DISABLE;
  sConfig.DAC_SampleAndHold = DAC_SAMPLEANDHOLD_DISABLE;
  sConfig.DAC_Trigger = DAC_TRIGGER_NONE;
  sConfig.DAC_Trigger2 = DAC_TRIGGER_NONE;
  sConfig.DAC_OutputBuffer = DAC_OUTPUTBUFFER_DISABLE;
  sConfig.DAC_ConnectOnChipPeripheral = DAC_CHIPCONNECT_INTERNAL;
  sConfig.DAC_UserTrimming = DAC_TRIMMING_FACTORY;
  if (HAL_DAC_ConfigChannel(&hdac3, &sConfig, DAC_CHANNEL_1) != HAL_OK)
  {
    Error_Handler();
  }
  /** DAC channel OUT2 config
  */
  if (HAL_DAC_ConfigChannel(&hdac3, &sConfig, DAC_CHANNEL_2) != HAL_OK)
  {
    Error_Handler();
  }

}

static void MX_TIM1_Init(void)
{

  TIM_SlaveConfigTypeDef sSlaveConfig = {0};
  TIM_MasterConfigTypeDef sMasterConfig = {0};
  TIMEx_BreakInputConfigTypeDef sBreakInputConfig = {0};
  TIM_OC_InitTypeDef sConfigOC = {0};
  TIM_BreakDeadTimeConfigTypeDef sBreakDeadTimeConfig = {0};

  htim1.Instance = TIM1;
  htim1.Init.Prescaler = ((TIM_CLOCK_DIVIDER) - 1);
  htim1.Init.CounterMode = TIM_COUNTERMODE_CENTERALIGNED1;
  htim1.Init.Period = ((PWM_PERIOD_CYCLES) / 2);
  htim1.Init.ClockDivision = TIM_CLOCKDIVISION_DIV2;
  htim1.Init.RepetitionCounter = (REP_COUNTER);
  htim1.Init.AutoReloadPreload = TIM_AUTORELOAD_PRELOAD_DISABLE;
  if (HAL_TIM_Base_Init(&htim1) != HAL_OK)
  {
    Error_Handler();
  }
  if (HAL_TIM_PWM_Init(&htim1) != HAL_OK)
  {
    Error_Handler();
  }
  sSlaveConfig.SlaveMode = TIM_SLAVEMODE_TRIGGER;
  sSlaveConfig.InputTrigger = TIM_TS_ITR1;
  if (HAL_TIM_SlaveConfigSynchro(&htim1, &sSlaveConfig) != HAL_OK)
  {
    Error_Handler();
  }
  sMasterConfig.MasterOutputTrigger = TIM_TRGO_OC4REF;
  sMasterConfig.MasterOutputTrigger2 = TIM_TRGO2_RESET;
  sMasterConfig.MasterSlaveMode = TIM_MASTERSLAVEMODE_DISABLE;
  if (HAL_TIMEx_MasterConfigSynchronization(&htim1, &sMasterConfig) != HAL_OK)
  {
    Error_Handler();
  }
//  sBreakInputConfig.Source = TIM_BREAKINPUTSOURCE_COMP1;
//  sBreakInputConfig.Enable = TIM_BREAKINPUTSOURCE_ENABLE;
//  sBreakInputConfig.Polarity = TIM_BREAKINPUTSOURCE_POLARITY_HIGH;
//  if (HAL_TIMEx_ConfigBreakInput(&htim1, TIM_BREAKINPUT_BRK2, &sBreakInputConfig) != HAL_OK)
//  {
//    Error_Handler();
//  }
//  sBreakInputConfig.Source = TIM_BREAKINPUTSOURCE_COMP2;
//  if (HAL_TIMEx_ConfigBreakInput(&htim1, TIM_BREAKINPUT_BRK2, &sBreakInputConfig) != HAL_OK)
//  {
//    Error_Handler();
//  }
//  sBreakInputConfig.Source = TIM_BREAKINPUTSOURCE_COMP4;
//  if (HAL_TIMEx_ConfigBreakInput(&htim1, TIM_BREAKINPUT_BRK2, &sBreakInputConfig) != HAL_OK)
//  {
//    Error_Handler();
//  }
  sConfigOC.OCMode = TIM_OCMODE_PWM1;
  sConfigOC.Pulse = 0;
  sConfigOC.OCPolarity = TIM_OCPOLARITY_HIGH;
  sConfigOC.OCNPolarity = TIM_OCNPOLARITY_HIGH;
  sConfigOC.OCFastMode = TIM_OCFAST_DISABLE;
  sConfigOC.OCIdleState = TIM_OCIDLESTATE_RESET;
  sConfigOC.OCNIdleState = TIM_OCNIDLESTATE_RESET;
  if (HAL_TIM_PWM_ConfigChannel(&htim1, &sConfigOC, TIM_CHANNEL_1) != HAL_OK)
  {
    Error_Handler();
  }
  if (HAL_TIM_PWM_ConfigChannel(&htim1, &sConfigOC, TIM_CHANNEL_2) != HAL_OK)
  {
    Error_Handler();
  }
  if (HAL_TIM_PWM_ConfigChannel(&htim1, &sConfigOC, TIM_CHANNEL_3) != HAL_OK)
  {
    Error_Handler();
  }
  sConfigOC.OCMode = TIM_OCMODE_PWM2;
  if (HAL_TIM_PWM_ConfigChannel(&htim1, &sConfigOC, TIM_CHANNEL_4) != HAL_OK)
  {
    Error_Handler();
  }
  sBreakDeadTimeConfig.OffStateRunMode = TIM_OSSR_ENABLE;
  sBreakDeadTimeConfig.OffStateIDLEMode = TIM_OSSI_ENABLE;
  sBreakDeadTimeConfig.LockLevel = TIM_LOCKLEVEL_1;
  sBreakDeadTimeConfig.DeadTime = ((DEAD_TIME_COUNTS) / 2);
  sBreakDeadTimeConfig.BreakState = TIM_BREAK_DISABLE;
  sBreakDeadTimeConfig.BreakPolarity = TIM_BREAKPOLARITY_HIGH;
  sBreakDeadTimeConfig.BreakFilter = 0;
  sBreakDeadTimeConfig.BreakAFMode = TIM_BREAK_AFMODE_INPUT;
  sBreakDeadTimeConfig.Break2State = TIM_BREAK2_ENABLE;
  sBreakDeadTimeConfig.Break2Polarity = TIM_BREAK2POLARITY_HIGH;
  sBreakDeadTimeConfig.Break2Filter = 3;
  sBreakDeadTimeConfig.Break2AFMode = TIM_BREAK_AFMODE_INPUT;
  sBreakDeadTimeConfig.AutomaticOutput = TIM_AUTOMATICOUTPUT_DISABLE;
  if (HAL_TIMEx_ConfigBreakDeadTime(&htim1, &sBreakDeadTimeConfig) != HAL_OK)
  {
    Error_Handler();
  }
  HAL_TIM_MspPostInit(&htim1);

}

static void MX_TIM2_Init(void)
{

  TIM_SlaveConfigTypeDef sSlaveConfig = {0};
  TIM_MasterConfigTypeDef sMasterConfig = {0};
  TIM_OC_InitTypeDef sConfigOC = {0};

  htim2.Instance = TIM2;
  htim2.Init.Prescaler = 0;
  htim2.Init.CounterMode = TIM_COUNTERMODE_UP;
  htim2.Init.Period = 65535;
  htim2.Init.ClockDivision = TIM_CLOCKDIVISION_DIV1;
  htim2.Init.AutoReloadPreload = TIM_AUTORELOAD_PRELOAD_DISABLE;
  if (HAL_TIM_Base_Init(&htim2) != HAL_OK)
  {
    Error_Handler();
  }
  if (HAL_TIM_OC_Init(&htim2) != HAL_OK)
  {
    Error_Handler();
  }
  sSlaveConfig.SlaveMode = TIM_SLAVEMODE_COMBINED_GATEDRESET;
  sSlaveConfig.InputTrigger = TIM_TS_ETRF;
  sSlaveConfig.TriggerPolarity = TIM_TRIGGERPOLARITY_NONINVERTED;
  sSlaveConfig.TriggerPrescaler = TIM_TRIGGERPRESCALER_DIV1;
  sSlaveConfig.TriggerFilter = 0;
  if (HAL_TIM_SlaveConfigSynchro(&htim2, &sSlaveConfig) != HAL_OK)
  {
    Error_Handler();
  }
  sMasterConfig.MasterOutputTrigger = TIM_TRGO_RESET;
  sMasterConfig.MasterSlaveMode = TIM_MASTERSLAVEMODE_DISABLE;
  if (HAL_TIMEx_MasterConfigSynchronization(&htim2, &sMasterConfig) != HAL_OK)
  {
    Error_Handler();
  }
  HAL_TIMEx_RemapConfig(&htim2, TIM_TIM2_ETR_COMP1);
  sConfigOC.OCMode = TIM_OCMODE_ACTIVE;
  sConfigOC.Pulse = 0x0005;
  sConfigOC.OCPolarity = TIM_OCPOLARITY_HIGH;
  sConfigOC.OCFastMode = TIM_OCFAST_DISABLE;
  if (HAL_TIM_OC_ConfigChannel(&htim2, &sConfigOC, TIM_CHANNEL_1) != HAL_OK)
  {
    Error_Handler();
  }

}

static void MX_TIM3_Init(void)
{

  TIM_SlaveConfigTypeDef sSlaveConfig = {0};
  TIM_MasterConfigTypeDef sMasterConfig = {0};
  TIM_OC_InitTypeDef sConfigOC = {0};

  htim3.Instance = TIM3;
  htim3.Init.Prescaler = 0;
  htim3.Init.CounterMode = TIM_COUNTERMODE_UP;
  htim3.Init.Period = 65535;
  htim3.Init.ClockDivision = TIM_CLOCKDIVISION_DIV1;
  htim3.Init.AutoReloadPreload = TIM_AUTORELOAD_PRELOAD_DISABLE;
  if (HAL_TIM_Base_Init(&htim3) != HAL_OK)
  {
    Error_Handler();
  }
  if (HAL_TIM_OC_Init(&htim3) != HAL_OK)
  {
    Error_Handler();
  }
  sSlaveConfig.SlaveMode = TIM_SLAVEMODE_COMBINED_GATEDRESET;
  sSlaveConfig.InputTrigger = TIM_TS_ETRF;
  sSlaveConfig.TriggerPolarity = TIM_TRIGGERPOLARITY_NONINVERTED;
  sSlaveConfig.TriggerPrescaler = TIM_TRIGGERPRESCALER_DIV1;
  sSlaveConfig.TriggerFilter = 0;
  if (HAL_TIM_SlaveConfigSynchro(&htim3, &sSlaveConfig) != HAL_OK)
  {
    Error_Handler();
  }
  sMasterConfig.MasterOutputTrigger = TIM_TRGO_RESET;
  sMasterConfig.MasterSlaveMode = TIM_MASTERSLAVEMODE_DISABLE;
  if (HAL_TIMEx_MasterConfigSynchronization(&htim3, &sMasterConfig) != HAL_OK)
  {
    Error_Handler();
  }
  HAL_TIMEx_RemapConfig(&htim3, TIM_TIM3_ETR_COMP2);
  sConfigOC.OCMode = TIM_OCMODE_ACTIVE;
  sConfigOC.Pulse = 0x0005;
  sConfigOC.OCPolarity = TIM_OCPOLARITY_HIGH;
  sConfigOC.OCFastMode = TIM_OCFAST_DISABLE;
  if (HAL_TIM_OC_ConfigChannel(&htim3, &sConfigOC, TIM_CHANNEL_1) != HAL_OK)
  {
    Error_Handler();
  }

}

static void MX_TIM4_Init(void)
{

  TIM_SlaveConfigTypeDef sSlaveConfig = {0};
  TIM_MasterConfigTypeDef sMasterConfig = {0};
  TIM_OC_InitTypeDef sConfigOC = {0};

  htim4.Instance = TIM4;
  htim4.Init.Prescaler = 0;
  htim4.Init.CounterMode = TIM_COUNTERMODE_UP;
  htim4.Init.Period = 65535;
  htim4.Init.ClockDivision = TIM_CLOCKDIVISION_DIV1;
  htim4.Init.AutoReloadPreload = TIM_AUTORELOAD_PRELOAD_DISABLE;
  if (HAL_TIM_Base_Init(&htim4) != HAL_OK)
  {
    Error_Handler();
  }
  if (HAL_TIM_OC_Init(&htim4) != HAL_OK)
  {
    Error_Handler();
  }
  sSlaveConfig.SlaveMode = TIM_SLAVEMODE_COMBINED_GATEDRESET;
  sSlaveConfig.InputTrigger = TIM_TS_ETRF;
  sSlaveConfig.TriggerPolarity = TIM_TRIGGERPOLARITY_NONINVERTED;
  sSlaveConfig.TriggerPrescaler = TIM_TRIGGERPRESCALER_DIV1;
  sSlaveConfig.TriggerFilter = 0;
  if (HAL_TIM_SlaveConfigSynchro(&htim4, &sSlaveConfig) != HAL_OK)
  {
    Error_Handler();
  }
  sMasterConfig.MasterOutputTrigger = TIM_TRGO_RESET;
  sMasterConfig.MasterSlaveMode = TIM_MASTERSLAVEMODE_DISABLE;
  if (HAL_TIMEx_MasterConfigSynchronization(&htim4, &sMasterConfig) != HAL_OK)
  {
    Error_Handler();
  }
  HAL_TIMEx_RemapConfig(&htim4, TIM_TIM4_ETR_COMP4);
  sConfigOC.OCMode = TIM_OCMODE_ACTIVE;
  sConfigOC.Pulse = 0x0005;
  sConfigOC.OCPolarity = TIM_OCPOLARITY_HIGH;
  sConfigOC.OCFastMode = TIM_OCFAST_DISABLE;
  if (HAL_TIM_OC_ConfigChannel(&htim4, &sConfigOC, TIM_CHANNEL_1) != HAL_OK)
  {
    Error_Handler();
  }

}

static void MX_TIM8_Init(void)
{

  TIM_HallSensor_InitTypeDef sConfig = {0};
  TIM_MasterConfigTypeDef sMasterConfig = {0};

  htim8.Instance = TIM8;
  htim8.Init.Prescaler = 0;
  htim8.Init.CounterMode = TIM_COUNTERMODE_UP;
  htim8.Init.Period = 65535;
  htim8.Init.ClockDivision = TIM_CLOCKDIVISION_DIV1;
  htim8.Init.RepetitionCounter = 0;
  htim8.Init.AutoReloadPreload = TIM_AUTORELOAD_PRELOAD_DISABLE;
  sConfig.IC1Polarity = TIM_ICPOLARITY_RISING;
  sConfig.IC1Prescaler = TIM_ICPSC_DIV1;
  sConfig.IC1Filter = M1_HALL_IC_FILTER;
  sConfig.Commutation_Delay = 0;
  if (HAL_TIMEx_HallSensor_Init(&htim8, &sConfig) != HAL_OK)
  {
    Error_Handler();
  }
  sMasterConfig.MasterOutputTrigger = TIM_TRGO_OC2REF;
  sMasterConfig.MasterOutputTrigger2 = TIM_TRGO2_OC2REF;
  sMasterConfig.MasterSlaveMode = TIM_MASTERSLAVEMODE_DISABLE;
  if (HAL_TIMEx_MasterConfigSynchronization(&htim8, &sMasterConfig) != HAL_OK)
  {
    Error_Handler();
  }

}

static void MX_USART3_UART_Init(void)
{

  huart3.Instance = USART3;
  huart3.Init.BaudRate = 115200;
  huart3.Init.WordLength = UART_WORDLENGTH_8B;
  huart3.Init.StopBits = UART_STOPBITS_1;
  huart3.Init.Parity = UART_PARITY_NONE;
  huart3.Init.Mode = UART_MODE_TX_RX;
  huart3.Init.HwFlowCtl = UART_HWCONTROL_NONE;
  huart3.Init.OverSampling = UART_OVERSAMPLING_16;
  huart3.Init.OneBitSampling = UART_ONE_BIT_SAMPLE_DISABLE;
  huart3.Init.ClockPrescaler = UART_PRESCALER_DIV1;
  huart3.AdvancedInit.AdvFeatureInit = UART_ADVFEATURE_NO_INIT;
  if (HAL_UART_Init(&huart3) != HAL_OK)
  {
    Error_Handler();
  }
  if (HAL_UARTEx_SetTxFifoThreshold(&huart3, UART_TXFIFO_THRESHOLD_1_8) != HAL_OK)
  {
    Error_Handler();
  }
  if (HAL_UARTEx_SetRxFifoThreshold(&huart3, UART_RXFIFO_THRESHOLD_1_8) != HAL_OK)
  {
    Error_Handler();
  }
  if (HAL_UARTEx_DisableFifoMode(&huart3) != HAL_OK)
  {
    Error_Handler();
  }

}

static void MX_GPIO_Init(void)
{
  GPIO_InitTypeDef GPIO_InitStruct = {0};

  /* GPIO Ports Clock Enable */
  __HAL_RCC_GPIOC_CLK_ENABLE();
  __HAL_RCC_GPIOF_CLK_ENABLE();
  __HAL_RCC_GPIOA_CLK_ENABLE();
  __HAL_RCC_GPIOB_CLK_ENABLE();

  /*Configure GPIO pin Output Level */
  HAL_GPIO_WritePin(HALL_V_SLCT_GPIO_Port, HALL_V_SLCT_Pin, GPIO_PIN_RESET);

  /*Configure GPIO pin : HALL_V_SLCT_Pin */
  GPIO_InitStruct.Pin = HALL_V_SLCT_Pin;
  GPIO_InitStruct.Mode = GPIO_MODE_OUTPUT_PP;
  GPIO_InitStruct.Pull = GPIO_NOPULL;
  GPIO_InitStruct.Speed = GPIO_SPEED_FREQ_LOW;
  HAL_GPIO_Init(HALL_V_SLCT_GPIO_Port, &GPIO_InitStruct);

}

/* USER CODE BEGIN 4 */

void startLoggingTask(void *argument)
{
	MCI_Handle_t * hMCI = GetMCI(M1);
	MCT_Handle_t * hMCT = GetMCT(M1);

	uint16_t i = 0;

  /* Infinite loop */
  for(;;)
  {
		if (i == 0)
		{
			for (i = 0; i < LOGGING_SIZE; i++)
			{
				loggingTemperature[i] = NTC_GetAvTemp_C(hMCT->pTemperatureSensor);
				loggingSpeed[i] = SPD_GetElSpeedDpp(hMCT->pSpeedSensorMain);
				osDelay(10000);
			}
		}
    osDelay(100);
  }
}

/* USER CODE END 4 */

__weak void startMediumFrequencyTask(void *argument)
{
  /* USER CODE BEGIN 5 */
  /* Infinite loop */
  for(;;)
  {
    osDelay(100);
  }
  /* USER CODE END 5 */
}

void startThrottleTask(void *argument)
{
  /* USER CODE BEGIN startThrottleTask */

	int16_t torqueref = 0;
	int16_t elOmega = 0;
	OpenLoop_Handle_t * pOpenLoopM1 = &OpenLoopM1;

	MCI_Handle_t * hMCI = GetMCI(M1);
	MCT_Handle_t * hMCT = GetMCT(M1);
	Throttle_Handle_t * pThrottleSensor = &ThrottleSensor;
	Derate_Handle_t * pDerateM1 = &DerateM1;

	HAL_GPIO_WritePin(HALL_V_SLCT_GPIO_Port, HALL_V_SLCT_Pin, GPIO_PIN_RESET);

	osDelay(100);

	Throttle_Init(pThrottleSensor);
	Derate_Init(pDerateM1);

//	MCI_ExecTorqueRamp( hMCI, 0, 0 );
//	MCI_StartMotor( hMCI );

  /* Infinite loop */
  for(;;)
  {
//		Throttle_CalcAvValue(pThrottleSensor);
//		torqueref = Throttle_CalcIqref(pThrottleSensor);
//		Derate_CalcTorque(pDerateM1, torqueref);
//		MCI_ExecTorqueRamp( hMCI, torqueref, 0 );

//		elOmega ++;
//		OL_UpdateElSpeed( pOpenLoopM1, elOmega );

    osDelay(500);
  }
  /* USER CODE END startThrottleTask */
}

 /**
  * @brief  Period elapsed callback in non blocking mode
  * @note   This function is called  when TIM6 interrupt took place, inside
  * HAL_TIM_IRQHandler(). It makes a direct call to HAL_IncTick() to increment
  * a global variable "uwTick" used as application time base.
  * @param  htim : TIM handle
  * @retval None
  */
void HAL_TIM_PeriodElapsedCallback(TIM_HandleTypeDef *htim)
{
  if (htim->Instance == TIM6) {
    HAL_IncTick();
  }
}

void Error_Handler(void)
{
}

/************************ (C) COPYRIGHT STMicroelectronics *****END OF FILE****/
